# TC37XPD register map
Vendor: Infineon; Series: ATVMC; File version: 100
CPU: other r0p0, little endian, MPU, FPU, vendor SysTick, 4 interrupt priority bits
Registers are 32-bit, read-write, reset 0x0 unless marked. A register's access mark holds for its fields unless they carry their own. Offsets are from the block's base; [hi:lo] are bit positions; lines under a group give offsets from that group; {n}, {i} and the like mark numbered series.

## CAN0 (part 2 of 3) — CAN
Base 0xF0200000
{0x8100+0x400*i} N[{i}] (i=0..3) group
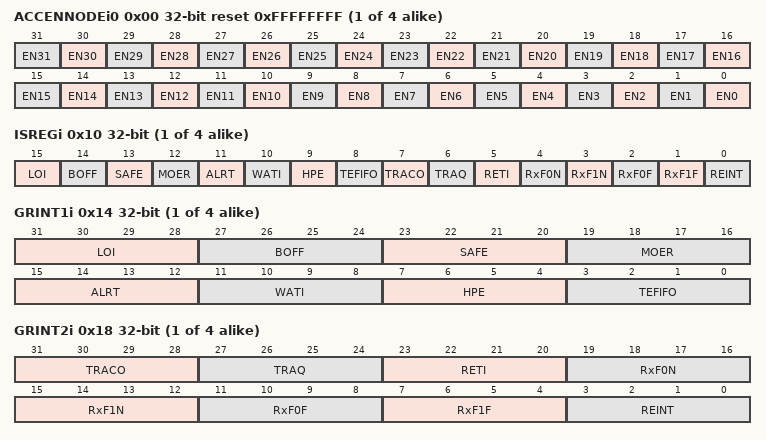
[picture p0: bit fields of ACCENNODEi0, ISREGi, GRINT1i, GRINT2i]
  0x00 ACCENNODEi0 reset 0xFFFFFFFF — Access Enable Register CAN Node 0 0 resetvalue={Application Reset:0x0FFFFFFFF}
    [n] EN{n} (n=0..31) — Access Enable for Master TAG ID 31 EN31. This bit enables write access to the module kernel addresses for transactions with the Master TAG ID y
  0x08 STARTADRi — Start Address Node 0 resetvalue={Application Reset:0x0}
    [15:2] START — Message RAM start START. The address within the RAM area of the MCMCAN of node i where the message RAM to be protected starts
  0x0C ENDADRi — End Address Node 0 resetvalue={Application Reset:0x0}
    [15:2] END — Message RAM end END. The address within the RAM area of the MCMCAN of node i where the message RAM to be protected ends
  0x10 ISREGi ro — Interrupt Signalling Register 0 resetvalue={Application Reset:0x0}
    [15] LOI — Last Error Interrupt LOI
    [14] BOFF — Bus Off Interrupt BOFF
    [13] SAFE — The safety counter interrupt ELO SAFE
    [12] MOER — Module error interrupt MOER
    [11] ALRT — An alert interrupt ALRT
    [10] WATI — A watermark interrupt has been reached WATI
    [9] HPE — A high priority event interrupt HPE
    [8] TEFIFO — A Transmit Event FIFO Incident interrupt TEFIFO
    [7] TRACO — A transmission control event interrupt TRACO
    [6] TRAQ — A transmission queue event interrupt TRAQ
    [5] RETI — A receive timeout event interrupt RETI
    [4] RxF0N — Receive FIFO0 got a new message interrupt RxF0N
    [3] RxF1N — Receive FIFO1 got a new message interrupt RxF1N
    [2] RxF0F — Receive FIFO0 is full interrupt RxF0F
    [1] RxF1F — Receive FIFO1 is full interrupt RxF1F
    [0] REINT — A message stored in a receive buffer interrupt REINT
  0x14 GRINT1i — Interrupt routing for Groups 1 0 resetvalue={Application Reset:0x0}
    [31:28] LOI — Last Error Interrupts LOI. The interrupt sources IR.PED Protocol Error in Data Phase and IR.PEA Protocol Error in Arbitration Phase are signalled here.
    [27:24] BOFF — Bus Off has been reached BOFF. Mapped to IRi.BO flag indication the change in Bus Off status. To get out of bus off the CCCRn.INIT bit has to be reset.
    [23:20] SAFE — Safety counter overflow SAFE. The interrupt node for IR.ELO showing a safety counter overflow
    [19:16] MOER — Module errors MOER. IR.WDI watchdog interrupt and IR.MRAF message RAM access failure are mapped here.
    [15:12] ALRT — ALERTS ALRT. All kind of alerts are mapped here. IR.EW warning status IR.EP error passive IR.TSW timestamp wrap around IR.TEFL Transmit Event FIFO Element Lost IR.RF0L Receive FIFO 0 Message Lost IR.RF1L Receive FIFO 1 Message Lost . The following TTCAN error messages and warnings are also shown here TTIR. CER Configuration Error TTIR.AW Application Watchdog TTIR.WT Watch Trigger TTIR.IWT Initialization Watch Trigger TTIR.ELC Error Level Changed TTIR.SE2 Scheduling Error 2 TTIR.SE1 Scheduling Error TTIR.TXO Tx Count Overflow TTIR.TXU TX Count Underflow TTIR.GTE Global Time Error TTIR.GTD Global Time Discontinuity and TTIR.GTW Global Time Wrap
    [11:8] WATI — Watermark interrupts WATI. are mapped here IR.TEFW Transmit FIFO warning interrupt reached IR.RF1W Receive FIFO 1 warning interrupt reached . IR.RF0W Receive FIFO 0 warning interrupt reached
    [7:4] HPE — High Priority Events HPE. are mapped here giving IR.HPM an interrupt level
    [3:0] TEFIFO — Transmit Event FIFO Incidents TEFIFO. are mapped here. IR.TEFF Transmit Event FIFO Full and IR.TEFN Transmit Event FIFO New Entry
  0x18 GRINT2i — Interrupt routing for Groups 2 0 resetvalue={Application Reset:0x0}
    [31:28] TRACO — Interrupts of the transmission control TRACO. can be assigned here. IR.TCF Transmission Cancellation Finished and IR.TF Transmission Completed . As an additional information the copy of a local time event is shown here with TTIR.SWT Stop Watch Event . Further on the TTIR.TTMI Trigger Time Event Internal TTIR.RTMI Register Time Mark TTIR.SOG Start of Gap TTIR.CSM Change of Synchronization Mode TTIR.SMC Start Matrix Cycle and TTIR.SBC Start of Basic Cycle are shown here.
    [27:24] TRAQ — Transmission Queue Events TRAQ. can be assigned here. IR.TFE Transmission FIFO Empty
    [23:20] RETI — Receive Timeouts RETI. can be assigned here. IR.TOO time out event and TE Timer Event
    [19:16] RxF0N — IR.RF0N RxF0N. Receive FIFO0 new message assigned to an interrupt node
    [15:12] RxF1N — IR.RF1N RxF1N. Receive FIFO1 new message assigned to an interrupt node
    [11:8] RxF0F — IR.RF0F RxF0F. Receive FIFO0 full interrupt assigned to an interrupt node
    [7:4] RxF1F — IR.RF1F RxF1F. Receive FIFO1 full interrupt assigned to an interrupt node
    [3:0] REINT — Message stored in dedicated receive buffer interrupt IR.DRX REINT. is assigned to interrupt node.
  0x20 NT group
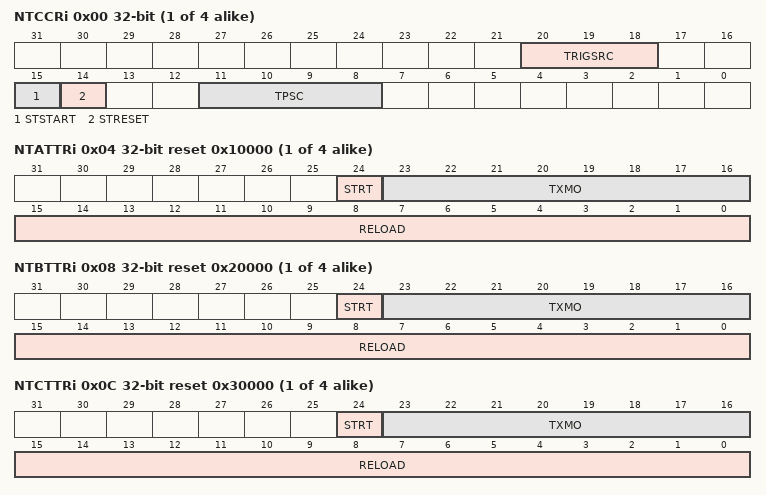
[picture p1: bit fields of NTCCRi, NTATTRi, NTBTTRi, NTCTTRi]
    0x00 NTCCRi — Node 0 Timer Clock Control Register resetvalue={Application Reset:0x0}
      [20:18] TRIGSRC — Trigger Source TRIGSRC. This bit selects the trigger source for the different modes in the node timer.
      [15] STSTART — Stamping Start STSTART. This bit is not implemented in TC39x A step silicon. This bit starts the external timer used for CAN FD messages. The source and the prescaler are identical to the timers A B C.
      [14] STRESET — Stamping Reset STRESET. This bit is not implemented in TC39x A step silicon. This bit gives the possibility to reset the time stamp for CAN FD messages.
      [11:8] TPSC — Timer Prescaler TPSC. The duration of one timer clock is given by TPSC 160 160 1 CAN bit times for all NTCCRi.TRIGSRC settings.
    0x04 NTATTRi access per field reset 0x10000 — Node 0 Timer A Transmit Trigger Register resetvalue={Application Reset:0x10000}
      [24] STRT rw — Timer Start STRT. This bit field controls the operation of the timer.
      [23:16] TXMO ro — Transmit Message Object TXMO. This transmit trigger is fixed to transmit buffer 1
      [15:0] RELOAD rw — Reload Value RELOAD. This bit field contains the reload value for the timer. The timer will restart when RELOAD is written.
    0x08 NTBTTRi access per field reset 0x20000 — Node 0 Timer B Transmit Trigger Register resetvalue={Application Reset:0x20000}
      [24] STRT rw — Timer Start STRT. This bit field controls the operation of the timer.
      [23:16] TXMO ro — Transmit Message Object TXMO. This transmit object is fixed to transmit buffer 2
      [15:0] RELOAD rw — Reload Value RELOAD. This bit field contains the reload value for the timer. The timer will restart when RELOAD is written.
    0x0C NTCTTRi access per field reset 0x30000 — Node 0 Timer C Transmit Trigger Register resetvalue={Application Reset:0x30000}
      [24] STRT rw — Timer Start STRT. This bit field controls the operation of the timer.
      [23:16] TXMO ro — Transmit Message Object TXMO. This transmit trigger is fixed to transmit buffer 3
      [15:0] RELOAD rw — Reload Value RELOAD. This bit field contains the reload value for the timer. The timer will restart when RELOAD is written.
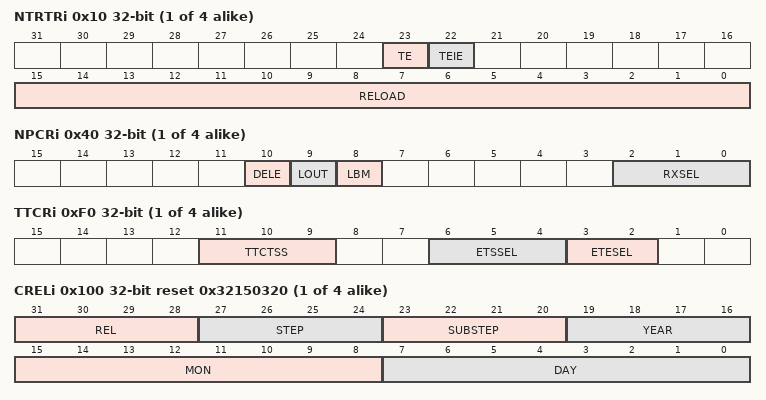
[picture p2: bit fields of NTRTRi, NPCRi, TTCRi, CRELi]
    0x10 NTRTRi — Node 0 Timer Receive Timeout Register resetvalue={Application Reset:0x0}
      [23] TE — Timer Event TE. This flag is set on a node timer transition from 1 to 0 in Receive Timeout Mode. This bit must be reset i.e Write to 8216 0 8217 by software writing a 8216 1 8217 has no effect. An interrupt request is generated if TEIE 1.
      [22] TEIE — Timer Event Interrupt Enable TEIE. This bit enables the node timer event interrupt of CAN node i. Bit field GRINT2.RETI selects the interrupt output line which becomes activated at this type of interrupt.
      [15:0] RELOAD — Reload Value RELOAD. This bit field contains the reload value for the timer. The timer will start when RELOAD 8800 0 is written. After half the time of the RELOAD value the interrupt flags of the receive buffers will be cleared automatically to ensure that no message receive will be missed.
  0x40 NPCRi — Node 0 Port Control Register resetvalue={Application Reset:0x0}
    [10] DELE — Enable destructive read on ECR0.CEL DELE. If this bit is set the destructive read on ECRi.CEL and on the PSR register takes place. Meaning that with read access on ECRi the CEL is reset. The same is true for the PSR register for the bits PXE RFDF RBRS RESI LEC and DLEC. After the destructive read it is advised to reset the bit again.
    [9] LOUT — Loop Back Mode Out LOUT. This bit is not implemented in TC39x A step silicon. The loop back bus is switched to the external CAN bus of the node.
    [8] LBM — Loop Back Mode LBM
    [2:0] RXSEL — Receive Select RXSEL. RXSEL selects one out of 8 possible receive inputs. The CAN receive signal is performed by the selected input. see the device related chapter for RXSEL
  0xF0 TTCRi — Time Trigger Control Register resetvalue={Application Reset:0x0}
    [11:9] TTCTSS — TTCapture Time Trigger Source Select TTCTSS. This bit selects the input source for the TT Capture Time TTCPT trigger. This register influences the stop watch event trigger
    [6:4] ETSSEL — External Trigger Source Selection ETSSEL. This bit fields selects the input source for the external reference message trigger.
    [3:2] ETESEL — External Trigger Event Selection ETESEL. This bit field defines the external trigger event that can be used to trigger the transmission of the reference message. The event causes the Event Trigger to be triggered. Control settings for this will not be influenced.
  0x100 CRELi ro reset 0x32150320 (reset mask 0xFFFFFFFC) — Core Release Register 0 resetvalue={Application Reset:0x32150320,Application Reset:0x32150323,Application Reset:0x32150320}
    [31:28] REL — Core Release REL. One digit BCD coded.
    [27:24] STEP — Step of Core Release STEP. One digit BCD coded.
    [23:20] SUBSTEP — Sub step of Core Release SUBSTEP. One digit BCD coded.
    [19:16] YEAR — Time Stamp Year
    [15:8] MON — Time Stamp Month
    [7:0] DAY — Time Stamp Day
  0x104 ENDNi ro reset 0x87654321 — Endian Register 0 resetvalue={Application Reset:0x087654321}
    [31:0] ETV — Endianness Test Value ETV. The endianness test value is 0x87654321.
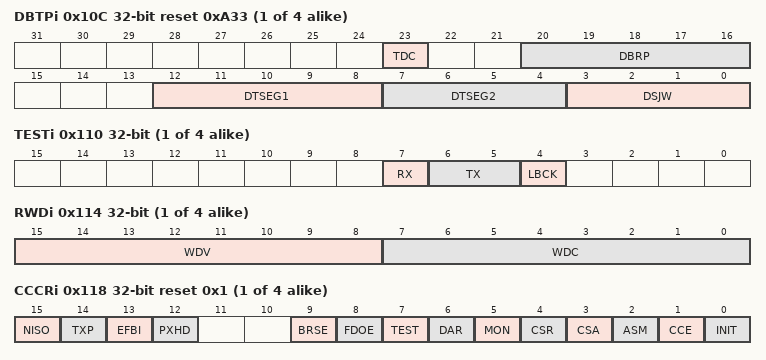
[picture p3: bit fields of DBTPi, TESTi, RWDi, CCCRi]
  0x10C DBTPi reset 0xA33 — Data Bit Timing Prescaler Register 0 resetvalue={Application Reset:0x0A33}
    [23] TDC — Transmitter Delay Compensation TDC. This bitfield is CCE and INIT protected. Writes will only have effect if both bits are set.
    [20:16] DBRP — Data Baud Rate Prescaler DBRP. This bitfield is CCE and INIT protected. Writes will only have effect if both bits are set. The value by which the oscillator frequency is divided for generating the bit time quanta. The bit time is built up from a multiple of this quanta. Valid values for the Baud Rate Prescaler are 8201 0 to 31. The actual interpretation by the hardware of this value is such that one more than the value programmed here is used.
    [12:8] DTSEG1 — Data time segment before sample point DTSEG1. This bitfield is CCE and INIT protected. Writes will only have effect if both bits are set. Valid values are 0 to 31. The actual interpretation by the hardware of this value is such that one more than the programmed value is used.
    [7:4] DTSEG2 — Data time segment after sample point DTSEG2. This bitfield is CCE and INIT protected. Writes will only have effect if both bits are set. Valid values are 0 to 15. The actual interpretation by the hardware of this value is such that one more than the programmed value is used.
    [3:0] DSJW — Data Re Synchronization Jump Width DSJW. This bitfield is CCE and INIT protected. Writes will only have effect if both bits are set. Valid values are 0 to 15. The actual interpretation by the hardware of this value is such that one more than the value programmed here is used.
  0x110 TESTi access per field (reset mask 0xFFFFFF7F) — Test Register 0 resetvalue={Application Reset:0x0}
    [7] RX ro — Receive Pin RX. Monitors the actual value of RX pin.
    [6:5] TX rw — Control of Transmit Pin TX. This bitfield is CCE and INIT protected. Writes will only have effect if both bits are set.
    [4] LBCK rw — Loop Back Mode LBCK. This bitfield is CCE and INIT protected. Writes will only have effect if both bits are set. This is the external loop back mode visible on the outside.
  0x114 RWDi access per field — RAM Watchdog 0 resetvalue={Application Reset:0x0}
    [15:8] WDV ro — Watchdog Value WDV. Actual Message RAM Watchdog Counter Value.
    [7:0] WDC rw — Watchdog Configuration WDC. This bitfield is CCE and INIT protected. Writes will only have effect if both bits are set. Start value of the Message RAM Watchdog Counter. With the reset value of 00 the counter is disabled.
  0x118 CCCRi access per field reset 0x1 — CC Control Register 0 resetvalue={Application Reset:0x1}
    [15] NISO rw — Non ISO Operation NISO. If this bit is set the M CAN uses the CAN FD frame format as specified by the Bosch CAN FD Specification V1.0.
    [14] TXP rw — Transmit Pause TXP. This bitfield is CCE and INIT protected. Writes will only have effect if both bits are set. If this bit is set the M CAN pauses for two CAN bit times before starting the next transmission after itself has successfully transmitted a frame see CROSSREFERENCE .
    [13] EFBI rw — Edge Filtering during Bus Integration EFBI. This bitfield is CCE and INIT protected. Writes will only have effect if both bits are set.
    [12] PXHD rw — Protocol Exception Handling Disable PXHD. This bitfield is CCE and INIT protected. Writes will only have effect if both bits are set.
    [9] BRSE rw — Bit Rate Switch Enable BRSE. This bitfield is CCE and INIT protected. Writes will only have effect if both bits are set.
    [8] FDOE rw — FD Operation Enable FDOE. This bitfield is CCE and INIT protected. Writes will only have effect if both bits are set.
    [7] TEST rw — Test Mode Enable TEST. The TEST register can only be set if CCE INIT and TEST are set. Writes to test will only have effect if all three bits are set.
    [6] DAR rw — Disable Automatic Retransmission DAR. This bitfield is CCE and INIT protected. Writes will only have effect if both bits are set.
    [5] MON rw — Bus Monitoring Mode MON. Bit MON can only be set by the Host when both CCE and INIT are set to 8216 1 8217 . The bit can be reset by the Host at any time. The bus monitoring mode corresponds to the Analyzer Mode of the MultiCAN module.
    [4] CSR rw — Clock Stop Request CSR
    [3] CSA ro — Clock Stop Acknowledge CSA
    [2] ASM rw — Restricted Operation Mode ASM. Bit ASM can only be set by the Host when both CCE and INIT are set to 8216 1 8217 . In can also be set by the M CAN . The bit can be reset by the Host at any time. For a description of the Restricted Operation Mode see paragraph Restricted Operation Mode.
    [1] CCE rw — Configuration Change Enable CCE
    [0] INIT rw — Initialization INIT. Due to the synchronization mechanism between the two clock domains there may be a delay until the value written to INIT can be read back. Therefore the programmer has to assure that the previous value written to INIT has been accepted by reading INIT before setting INIT to a new value.
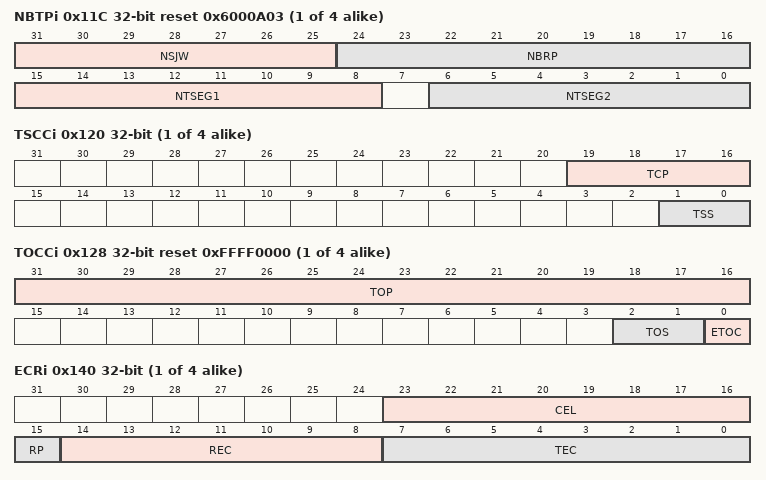
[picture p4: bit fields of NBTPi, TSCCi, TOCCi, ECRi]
  0x11C NBTPi reset 0x6000A03 — Nominal Bit Timing Prescaler Register 0 resetvalue={Application Reset:0x6000A03}
    [31:25] NSJW — Re Synchronization Jump Width NSJW. This bitfield is CCE and INIT protected. Writes will only have effect if both bits are set. Valid values are 0 to 127. The actual interpretation by the hardware of this value is such that one more than the value programmed here is used.
    [24:16] NBRP — Baud Rate Prescaler NBRP. This bitfield is CCE and INIT protected. Writes will only have effect if both bits are set. The value by which the oscillator frequency is divided for generating the bit time quanta. The bit time is built up from a multiple of this quanta. Valid values for the Baud Rate Prescaler are 0 to 511. The actual interpretation by the hardware of this value is such that one more than the value programmed here is used.
    [15:8] NTSEG1 — Nominal Time segment before sample point NTSEG1. This bitfield is CCE and INIT protected. Writes will only have effect if both bits are set. Valid values are 1 to 255. The actual interpretation by the hardware of this value is such that one more than the programmed value is used.
    [6:0] NTSEG2 — Nominal Time segment after sample point NTSEG2. This bitfield is CCE and INIT protected. Writes will only have effect if both bits are set. Valid values are 1 to 127. The actual interpretation by the hardware of this value is such that one more than the programmed value is used.
  0x120 TSCCi — Timestamp Counter Configuration 0 resetvalue={Application Reset:0x0}
    [19:16] TCP — Timestamp Counter Prescaler TCP. This bitfield is CCE and INIT protected. Writes will only have effect if both bits are set. Configures the timestamp and timeout counters time unit in multiples of CAN bit times 8201 1 8230 16 8201 . The actual interpretation by the hardware of this value is such that one more than the value programmed here is used. With CAN FD an external counter is required for timestamp generation TSS 8220 10 8221
    [1:0] TSS — Time segment before sample point TSS. This bitfield is CCE and INIT protected. Writes will only have effect if both bits are set.
  0x124 TSCVi — Timestamp Counter Value 0 resetvalue={Application Reset:0x0}
    [15:0] TSC — Timestamp Counter TSC. The internal external Timestamp Counter value is captured on start of frame both Rx and Tx . When TSCC.TSS 8220 01 8221 the Timestamp Counter is incremented in multiples of CAN bit times 8201 1 8230 16 8201 depending on the configuration of TSCC.TCP. A wrap around sets interrupt flag IR.TSW. Write access resets the counter to zero. When TSCC.TSS 160 160 8220 10 8221 TSC reflects the external Timestamp Counter value. A write access has no impact. A 8220 wrap around 8221 is a change of the Timestamp Counter value from non zero to zero not caused by write access to TSCV.
  0x128 TOCCi reset 0xFFFF0000 — Timeout Counter Configuration 0 resetvalue={Application Reset:0x0FFFF0000}
    [31:16] TOP — Timeout Period TOP. This bitfield is CCE and INIT protected. Writes will only have effect if both bits are set. Start value of the Timeout Counter down counter . Configures the Timeout Period.
    [2:1] TOS — Timeout Select TOS. This bitfield is CCE and INIT protected. Writes will only have effect if both bits are set. When operating in Continuous mode a write to TOCV presets the counter to the value configured by TOCC.TOP and continues down counting. When the Timeout Counter is controlled by one of the FIFOs an empty FIFO presets the counter to the value configured by TOCC.TOP. Down counting is started when the first FIFO element is stored.
    [0] ETOC — Enable Timeout Counter ETOC. This bitfield is CCE and INIT protected. Writes will only have effect if both bits are set. For use of timeout function with CAN FD see chapter Timeout Counter.
  0x12C TOCVi reset 0xFFFF — Timeout Counter Value 0 resetvalue={Application Reset:0x0FFFF}
    [15:0] TOC — Timeout Counter TOC. The Timeout Counter is decremented in multiples of CAN bit times 8201 1 8230 16 8201 depending on the configuration of TSCC.TCP. When decremented to zero interrupt flag IR.TOO is set and the Timeout Counter is stopped. Start and reset restart conditions are configured via TOCC.TOS. Any write access will lead to clearing of the counter.
  0x140 ECRi ro — Error Counter Register 0 resetvalue={Application Reset:0x0}
    [23:16] CEL — CAN Error Logging CEL. The counter is incremented each time when a CAN protocol error causes the Transmit Error Counter or the Receive Error Counter to be incremented. It is reset by read access to CEL. The counter stops at 0xFF the next increment of TEC or REC sets interrupt flag IR.ELO. The counter is reset on read if the bit NPCRi.DELE is set for the node.
    [15] RP — Receive Error Passive RP
    [14:8] REC — Receive Error Counter REC. Actual state of the Receive Error Counter values between 0 and 127 When CCCR.ASM is set the CAN protocol controller does not increment TEC and REC when a CAN protocol error is detected but CEL is still incremented.
    [7:0] TEC — Transmit Error Counter TEC. Actual state of the Transmit Error Counter values between 0 and 255 When CCCR.ASM is set the CAN protocol controller does not increment TEC and REC when a CAN protocol error is detected but CEL is still incremented.
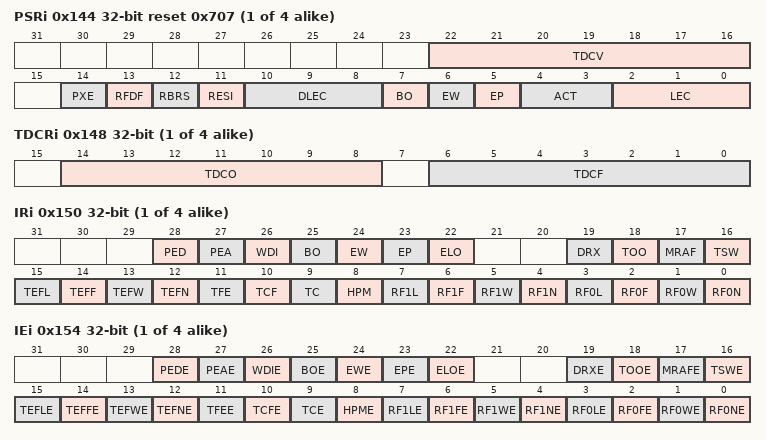
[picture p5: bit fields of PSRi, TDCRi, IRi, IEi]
  0x144 PSRi ro reset 0x707 — Protocol Status Register 0 resetvalue={Application Reset:0x707}
    [22:16] TDCV — Transmitter Delay Compensation Value TDCV. Position of the secondary sample point defined by the sum of the measured delay from TX to RX and TDCR.TDCO. The SSP position is in the data phase the number of mtq between the start of the transmitted bit and the secondary sample point. Valid values are 0 to 127 mtq.
    [14] PXE — Protocol Exception Event PXE. This bit is reset after read access if NPCRi.DELE is set.
    [13] RFDF — Received a CAN FD Message RFDF. This bit is set independent of acceptance filtering. This bit is reset after read access if NPCRi.DELE is set.
    [12] RBRS — BRS flag of last received CAN FD Message RBRS. This bit is set together with REDF independent of acceptance filtering. This bit is reset after read access if NPCRi.DELE is set.
    [11] RESI — ESI flag of last received CAN FD Message RESI. This bit is set together with REDF independent of acceptance filtering. This bit is reset after read access if NPCRi.DELE is set.
    [10:8] DLEC — Data Phase Last Error Code DLEC. Type of last error that occurred in the data phase of a CAN FD format frame with its BRS flag set. Coding is the same as for LEC. This field will be cleared to zero when a CAN FD format frame with its BRS flag set has been transferred reception or transmission without error. This bit field is set to 0x7 on read if NPCRi.DELE is set. When a frame in CAN FD format has reached the data phase with BRS flag set the next CAN event error or valid frame will be shown in DLEC instead of LEC. An error in a fixed stuff bit of a CAN FD CRC sequence will be shown as a Form Error not Stuff Error.
    [7] BO — Bus Off Status BO
    [6] EW — Warning Status EW
    [5] EP — Error Passive EP
    [4:3] ACT — Activity ACT. Monitors the module s CAN communication state. ACT is set to 00 by a Protocol Exception Event.
    [2:0] LEC — Last Error Code LEC. The LEC indicates the type of the last error to occur on the CAN bus. This field will be cleared to 8216 0 8217 when a message has been transferred reception or transmission without error. This bit field is set to 0x7 on read if NPCRi.DELE is set. The Bus Off recovery sequence see ISO11898 1 cannot be shortened by setting or resetting CCCR.INIT. If the device goes Bus Off it will set CCCR.INIT of its own accord stopping all bus activities. Once CCCR.INIT has been cleared by the CPU the device will then wait for 129 occurrences of Bus Idle 129 11 consecutive recessive bits before resuming normal operation. At the end of the Bus Off recovery sequence the Error Management Counters will be reset. During the waiting time after the resetting of CCCR.INIT each time a sequence of 11 recessive bits has been monitored a Bit0Error code is written to PSR.LEC enabling the CPU to readily check up whether the CAN bus is stuck at dominant or continuously disturbed and to monitor the Bus Off recovery sequence. ECR.REC is used to count these sequences.
  0x148 TDCRi — Transmitter Delay Compensation Register 0 resetvalue={Application Reset:0x0}
    [14:8] TDCO — Transmitter Delay Compensation Offset TDCO. This bitfield is CCE and INIT protected. Writes will only have effect if both bits are set. Offset value defining the distance between the measured delay from TX to RX and the secondary sample point. Valid values are 0 to 127 mtq. The duration of one mtq is equal to the fASYNi clock period.
    [6:0] TDCF — Transmitter Delay Compensation Filter Window Length TDCF. This bitfield is CCE and INIT protected. Writes will only have effect if both bits are set. Defines the minimum value for the Secondary Sample Point position dominant edges on RX that would result in an earlier Secondary Sample Point position are ignored for transmitter delay measurement. This feature is enabled when TDCF is configured to a value greater than TDCO. Valid values are from 0 to 127 mtq.
  0x150 IRi — Interrupt Register 0 resetvalue={Application Reset:0x0}
    [28] PED — Protocol Error in Data Phase PED. Data Bit Time is used
    [27] PEA — Protocol Error in Arbitration Phase PEA. Nominal Bit Time is used
    [26] WDI — Watchdog Interrupt WDI
    [25] BO — Bus Off Status BO
    [24] EW — Warning Status EW
    [23] EP — Error Passive EP
    [22] ELO — Error Logging Overflow ELO
    [19] DRX — Message stored to Dedicated Rx Buffer DRX. The flag is set whenever a received message has been stored into a dedicated Rx Buffer.
    [18] TOO — Timeout Occurred TOO
    [17] MRAF — Message RAM Access Failure MRAF. The flag is set when the Rx Handler has not completed acceptance filtering or storage of an accepted message until the arbitration field of the following message has been received. In this case acceptance filtering or message storage is aborted and the Rx Handler starts processing of the following message. was not able to write a message to the Message RAM. In this case message storage is aborted. In both cases the FIFO put index is not updated resp. the New Data flag for a dedicated Rx Buffer is not set a partly stored message is overwritten when the next message is stored to this location. The flag is also set when the Tx Handler was not able to read a message from the Message RAM in time. In this case message transmission is aborted. In case of a Tx Handler access failure the M CAN is switched into Restricted Operation Mode. To leave Restricted Operation Mode the Host CPU has to reset CCCR.ASM.
    [16] TSW — Timestamp Wraparound TSW
    [15] TEFL — Tx Event FIFO Element Lost TEFL
    [14] TEFF — Tx Event FIFO Full TEFF
    [13] TEFW — Tx Event FIFO Watermark Reached TEFW
    [12] TEFN — Tx Event FIFO New Entry TEFN
    [11] TFE — Tx FIFO Empty TFE
    [10] TCF — Transmission Cancellation Finished TCF
    [9] TC — Transmission Completed TC
    [8] HPM — High Priority Message HPM
    [7] RF1L — Rx FIFO 1 Message Lost RF1L
    [6] RF1F — Rx FIFO 1 Full RF1F
    [5] RF1W — Rx FIFO 1 Watermark Reached RF1W
    [4] RF1N — Rx FIFO 1 New Message RF1N
    [3] RF0L — Rx FIFO 0 Message Lost RF0L
    [2] RF0F — Rx FIFO 0 Full RF0F
    [1] RF0W — Rx FIFO 0 Watermark Reached RF0W
    [0] RF0N — Rx FIFO 0 New Message RF0N
  0x154 IEi — Interrupt Enable 0 resetvalue={Application Reset:0x0}
    [28] PEDE — Protocol Error in Data Phase Enable PEDE
    [27] PEAE — Protocol Error in Arbitration Phase Enable PEAE
    [26] WDIE — Watchdog Interrupt Enable WDIE
    [25] BOE — Bus Off Status Interrupt Enable BOE
    [24] EWE — Warning Status Interrupt Enable EWE
    [23] EPE — Error Passive Interrupt Enable EPE
    [22] ELOE — Error Logging Overflow Interrupt Enable ELOE
    [19] DRXE — Message stored to Dedicated Rx Buffer Interrupt Enable DRXE
    [18] TOOE — Timeout Occurred Interrupt Enable TOOE
    [17] MRAFE — Message RAM Access Failure Interrupt Enable MRAFE
    [16] TSWE — Timestamp Wraparound Interrupt Enable TSWE
    [15] TEFLE — Tx Event FIFO Element Lost Interrupt Enable TEFLE
    [14] TEFFE — Tx Event FIFO Full Interrupt Enable TEFFE
    [13] TEFWE — Tx Event FIFO Watermark Reached Interrupt Enable TEFWE
    [12] TEFNE — Tx Event FIFO New Entry Interrupt Enable TEFNE
    [11] TFEE — Tx FIFO Empty Interrupt Enable TFEE
    [10] TCFE — Transmission Cancellation Finished Interrupt Enable TCFE
    [9] TCE — Transmission Completed Interrupt Enable TCE
    [8] HPME — High Priority Message Interrupt Enable HPME
    [7] RF1LE — Rx FIFO 1 Message Lost Interrupt Enable RF1LE
    [6] RF1FE — Rx FIFO 1 Full Interrupt Enable RF1FE
    [5] RF1WE — Rx FIFO 1 Watermark Reached Interrupt Enable RF1WE
    [4] RF1NE — Rx FIFO 1 New Message Interrupt Enable RF1NE
    [3] RF0LE — Rx FIFO 0 Message Lost Interrupt Enable RF0LE
    [2] RF0FE — Rx FIFO 0 Full Interrupt Enable RF0FE
    [1] RF0WE — Rx FIFO 0 Watermark Reached Interrupt Enable RF0WE
    [0] RF0NE — Rx FIFO 0 New Message Interrupt Enable RF0NE
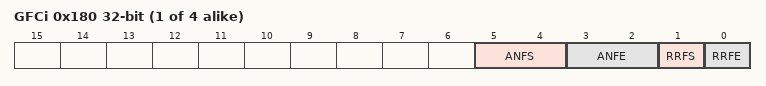
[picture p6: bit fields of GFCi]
  0x180 GFCi — Global Filter Configuration 0 resetvalue={Application Reset:0x0}
    [5:4] ANFS — Accept Non matching Frames Standard ANFS. This bitfield is CCE and INIT protected. Writes will only have effect if both bits are set. Defines how received messages with 11 bit IDs that do not match any element of the filter list are treated.
    [3:2] ANFE — Accept Non matching Frames Extended ANFE. This bitfield is CCE and INIT protected. Writes will only have effect if both bits are set. Defines how received messages with 29 bit IDs that do not match any element of the filter list are treated.
    [1] RRFS — Reject Remote Frames Standard RRFS. This bitfield is CCE and INIT protected. Writes will only have effect if both bits are set.
    [0] RRFE — Reject Remote Frames Extended RRFE. This bitfield is CCE and INIT protected. Writes will only have effect if both bits are set.
